AUTOSAR XML (schema 00048)
package /ComponentTypes
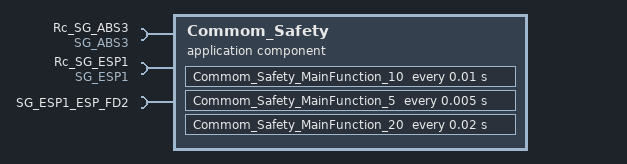
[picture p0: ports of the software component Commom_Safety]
  application sw component type Commom_Safety
    require port Rc_SG_ABS3: nonqueued-receiver-com-spec{data-element=SG_ABS3, uses-end-to-end-protection=true, alive-timeout=0.2, enable-update=true, init-value=fields=[ABSFailSts:1, CheckSum_ABS3:0, EBDFailSts:0, RollingCounter_ABS3:0, VehOdoInfo:0, VehOdoInfoSts:1, VehSpd:0, VehSpdVld:0]}, required-interface=SG_ABS3
    require port Rc_SG_ESP1: nonqueued-receiver-com-spec{data-element=SG_ESP1, uses-end-to-end-protection=true, alive-timeout=0.2, enable-update=true, init-value=fields=[CheckSum_ESP1:0, ESPActvInfoLmp:0, ESPFailSts:0, ESPFuncOffSts:0, RollingCounter_ESP1:0]}, required-interface=SG_ESP1
    require port SG_ESP1_ESP_FD2: nonqueued-receiver-com-spec{data-element=SG_ESP1_ESP_FD2, uses-end-to-end-protection=true, alive-timeout=0.2, enable-update=true, init-value=fields=[CheckSum_ESP1_FD:0, ESPActvInfoLmp_FD:0, ESPFailSts_FD:0, ESPFuncOffSts_FD:0, RollingCounter_ESP1_FD:0]}, required-interface=SG_ESP1_ESP_FD2
    behavior Commom_Safety_InternalBehavior: data-type-mapping=DataTypeMappings_DEV
      timing event TMT_Runnable: start-on-event=Commom_Safety_MainFunction_10, period=0.01
      init event Common_Safety_InitEvent: start-on-event=Commom_Safety_Init
      timing event TMT_Commom_Safety_MainFunction_5: start-on-event=Commom_Safety_MainFunction_5, period=0.005
      timing event TMT_Commom_Safety_MainFunction_20: start-on-event=Commom_Safety_MainFunction_20, period=0.02
      4 x runnable:
        Commom_Safety_MainFunction_10
          data-receive-point-by-arguments:
            access REC_Rc_SG_ABS3_SG_ABS3: accessed-variable=Rc_SG_ABS3.SG_ABS3
            access REC_SG_ESP1_SG_ESP1: accessed-variable=Rc_SG_ESP1.SG_ESP1
            access REC_SG_ESP1_ESP_FD2_SG_ESP1_ESP_FD2: accessed-variable=SG_ESP1_ESP_FD2.SG_ESP1_ESP_FD2
        Commom_Safety_Init
        Commom_Safety_MainFunction_5
        Commom_Safety_MainFunction_20
  swc implementation Commom_Safety_Implementation: behavior=Commom_Safety_InternalBehavior
